# STM32MP157 register map
File version: 1.7
CPU: CM4 r0p1, little endian, no MPU, FPU, 4 interrupt priority bits
Registers are 32-bit, read-write, reset 0x0 unless marked. A register's access mark holds for its fields unless they carry their own. Offsets are from the block's base; [hi:lo] are bit positions; {n}, {i} and the like mark numbered series; 'fields as' and 'values as' point back to an identical list.

## RCC (part 2 of 2)
Base 0x50000000
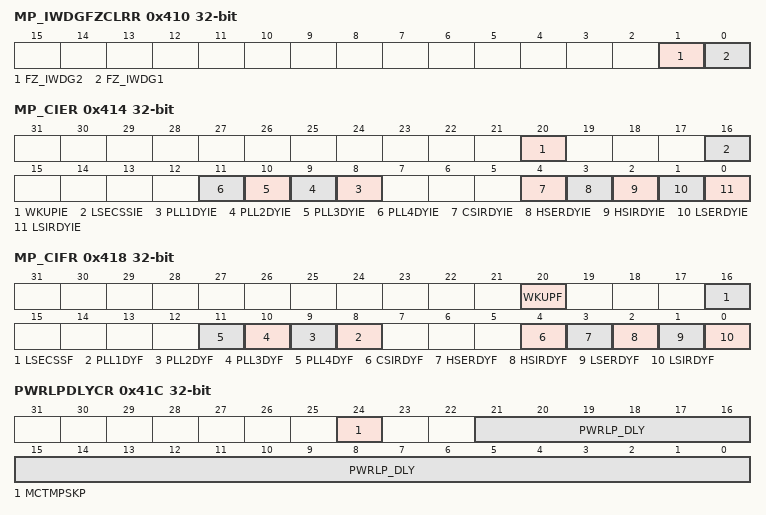
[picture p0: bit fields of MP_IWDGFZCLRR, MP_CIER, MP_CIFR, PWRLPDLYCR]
0x410 MP_IWDGFZCLRR — This register is used by the BOOTROM in order to unfreeze the IWDGs clocks. Writing has no effect, reading will return the effective values of the corresponding bits. Writing a clears the corresponding bit to . If TZEN = , this register can only be modified in secure mode.
  [1] FZ_IWDG2, [0] FZ_IWDG1
0x414 MP_CIER — This register shall be used by the MPU to control the interrupt source enable. Refer to Section10.5: RCC interrupts for more details. If TZEN = , this register can only be modified in secure mode.
  [20] WKUPIE, [16] LSECSSIE, [n+7] PLL{n}DYIE (n=1..4), [4] CSIRDYIE, [3] HSERDYIE, [2] HSIRDYIE, [1] LSERDYIE, [0] LSIRDYIE
0x418 MP_CIFR — This register shall be used by the MPU in order to read and clear the interrupt flags.Writing has no effect, writing will clear the corresponding flag.Refer to Section10.5: RCC interrupts for more details. If TZEN = , this register can only be modified in secure mode.
  [20] WKUPF, [16] LSECSSF, [n+7] PLL{n}DYF (n=1..4), [4] CSIRDYF, [3] HSERDYF, [2] HSIRDYF, [1] LSERDYF, [0] LSIRDYF
0x41C PWRLPDLYCR — This register is used to program the delay between the moment where the system exits from one of the Stop modes, and the moment where it is allowed to enable the PLLs and provide a clock to bridges and processors. If TZEN = , this register can only be modified in secure mode.
  [24] MCTMPSKP, [21:0] PWRLP_DLY
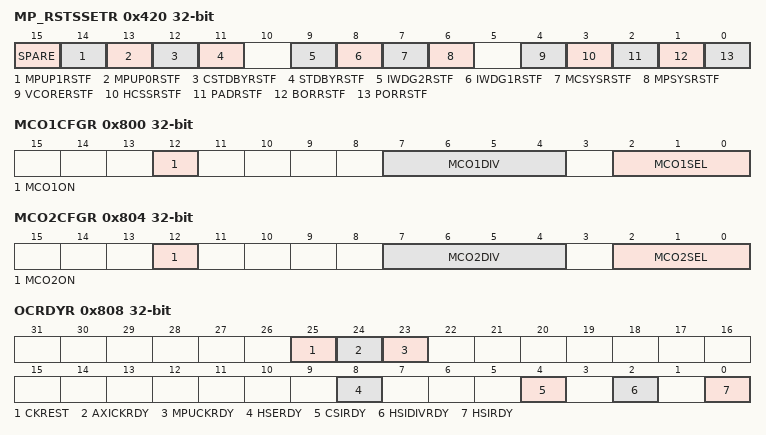
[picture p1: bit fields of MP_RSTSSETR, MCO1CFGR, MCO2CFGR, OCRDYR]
0x420 MP_RSTSSETR — This register is dedicated to the BOOTROM code in order to update the reset source. This register is updated by the BOOTROM code, after a power-on reset (por_rst), a system reset (nreset), or an exit from Standby or CStandby. The application software shall not use this register. In order to identify the reset source, the MPU application must use RCC MPU Reset Status Clear Register (RCC_MP_RSTSCLRR), and the MCU application must use the RCC MCU Reset Status Clear Register (RCC_MC_RSTSCLRR).Writing has no effect, reading will return the effective values of the corresponding bits. Writing a sets the corresponding bit to .Refer to Section10.3.13: Reset source identification for details.The register is located in VDDCORE.If TZEN = , this register can only be modified in secure mode.
  [15] SPARE, [14] MPUP1RSTF, [13] MPUP0RSTF, [12] CSTDBYRSTF, [11] STDBYRSTF, [9] IWDG2RSTF, [8] IWDG1RSTF, [7] MCSYSRSTF, [6] MPSYSRSTF, [4] VCORERSTF, [3] HCSSRSTF, [2] PADRSTF, [1] BORRSTF, [0] PORRSTF
0x800 MCO1CFGR — This register is used to select the clock generated on MCO1 output.
  [12] MCO1ON, [7:4] MCO1DIV, [2:0] MCO1SEL
0x804 MCO2CFGR — This register is used to select the clock generated on MCO2 output.
  [12] MCO2ON, [7:4] MCO2DIV, [2:0] MCO2SEL
0x808 OCRDYR ro — This is a read-only access register, It contains the status flags of oscillators. Writing has no effect.
  [25] CKREST, [24] AXICKRDY, [23] MPUCKRDY, [8] HSERDY, [4] CSIRDY, [2] HSIDIVRDY, [0] HSIRDY
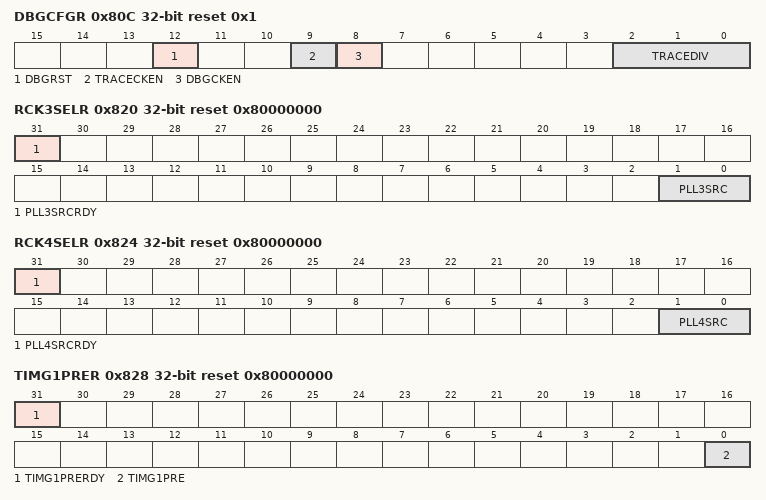
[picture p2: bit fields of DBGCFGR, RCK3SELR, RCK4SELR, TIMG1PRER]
0x80C DBGCFGR reset 0x1 — This is register contains the enable control of the debug and trace function, and the clock divider for the trace function.
  [12] DBGRST, [9] TRACECKEN, [8] DBGCKEN, [2:0] TRACEDIV
0x820 RCK3SELR access per field reset 0x80000000 — This register is used to select the reference clock for PLL3. If TZEN = MCKPROT = , this register can only be modified in secure mode.
  [31] PLL3SRCRDY ro, [1:0] PLL3SRC rw
0x824 RCK4SELR access per field reset 0x80000000 — This register is used to select the reference clock for PLL4.
  [31] PLL4SRCRDY ro, [1:0] PLL4SRC rw
0x828 TIMG1PRER access per field reset 0x80000000 — This register is used to control the prescaler value of timers located into APB1 domain. It concerns TIM2, TIM3, TIM4, TIM5, TIM6, TIM7, TIM12, TIM13 and TIM14. Refer to Section: Sub-system clock generation for additional information.
  [31] TIMG1PRERDY ro, [0] TIMG1PRE rw
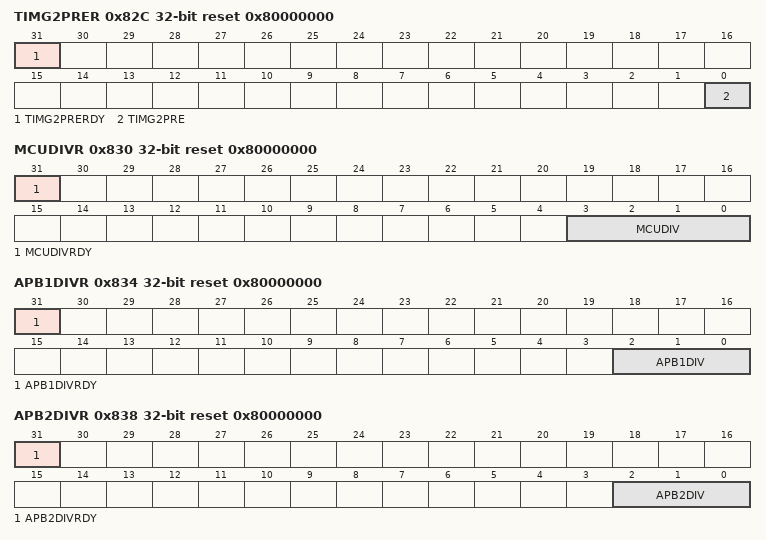
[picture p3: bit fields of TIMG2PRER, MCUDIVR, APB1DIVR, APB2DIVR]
0x82C TIMG2PRER access per field reset 0x80000000 — This register is used to control the prescaler value of timers located into APB2 domain. It concerns TIM1, TIM8, TIM15, TIM16, and TIM17. Refer to Section: Sub-system clock generation for additional information.
  [31] TIMG2PRERDY ro, [0] TIMG2PRE rw
0x830 MCUDIVR access per field reset 0x80000000 — This register is used to control the MCU sub-system clock prescaler. Refer to Section: Sub-system clock generation for additional information. If TZEN = , this register can only be modified in secure mode.
  [31] MCUDIVRDY ro, [3:0] MCUDIV rw
0x834 APB1DIVR access per field reset 0x80000000 — This register is used to control the APB1 clock prescaler. Refer to section Section1.4.6.3: Sub-System Clock Generation for additional information.
  [31] APB1DIVRDY ro, [2:0] APB1DIV rw
0x838 APB2DIVR access per field reset 0x80000000 — This register is used to control the APB2 clock prescaler. Refer to Section: Sub-system clock generation for additional information.
  [31] APB2DIVRDY ro, [2:0] APB2DIV rw
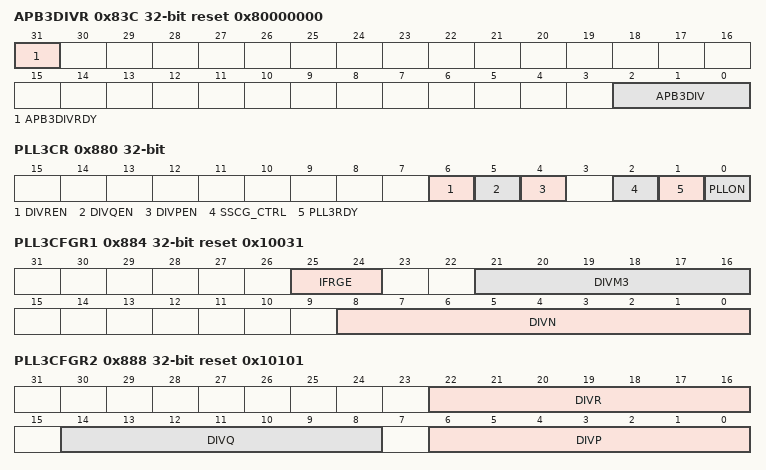
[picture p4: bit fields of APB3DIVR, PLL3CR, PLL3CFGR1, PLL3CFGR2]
0x83C APB3DIVR access per field reset 0x80000000 — This register is used to control the APB3 clock prescaler. Refer to Section: Sub-system clock generation for additional information.
  [31] APB3DIVRDY ro, [2:0] APB3DIV rw
0x880 PLL3CR access per field — This register is used to control the PLL3. If TZEN = MCKPROT = , this register can only be modified in secure mode.
  [6] DIVREN rw, [5] DIVQEN rw, [4] DIVPEN rw, [2] SSCG_CTRL rw, [1] PLL3RDY ro, [0] PLLON rw
0x884 PLL3CFGR1 reset 0x10031 — This register is used to configure the PLL3. If TZEN = MCKPROT = , this register can only be modified in secure mode.
  [25:24] IFRGE, [21:16] DIVM3, [8:0] DIVN
0x888 PLL3CFGR2 reset 0x10101 — This register is used to configure the PLL3. If TZEN = MCKPROT = , this register can only be modified in secure mode.
  [22:16] DIVR, [14:8] DIVQ, [6:0] DIVP
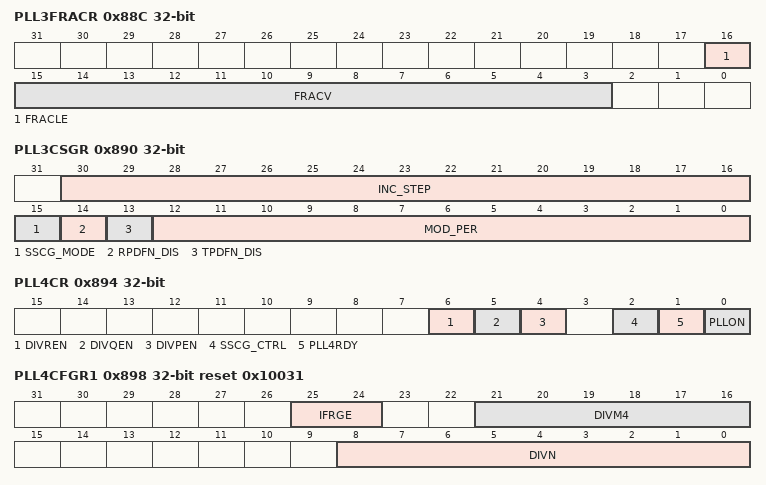
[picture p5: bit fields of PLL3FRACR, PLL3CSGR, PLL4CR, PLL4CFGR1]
0x88C PLL3FRACR — This register is used to fine-tune the frequency of the PLL3 VCO. If TZEN = MCKPROT = , this register can only be modified in secure mode.
  [16] FRACLE, [15:3] FRACV
0x890 PLL3CSGR — This register is used to configure the PLL3.It is not recommended to change the content of this register when the PLL3 is enabled (PLLON = ). Refer to Section: Using the PLLs in spread spectrum mode for details. If TZEN = MCKPROT = , this register can only be modified in secure mode.
  [30:16] INC_STEP, [15] SSCG_MODE, [14] RPDFN_DIS, [13] TPDFN_DIS, [12:0] MOD_PER
0x894 PLL4CR access per field — This register is used to control the PLL4.
  [6] DIVREN rw, [5] DIVQEN rw, [4] DIVPEN rw, [2] SSCG_CTRL rw, [1] PLL4RDY ro, [0] PLLON rw
0x898 PLL4CFGR1 reset 0x10031 — This register is used to configure the PLL4.
  [25:24] IFRGE, [21:16] DIVM4, [8:0] DIVN
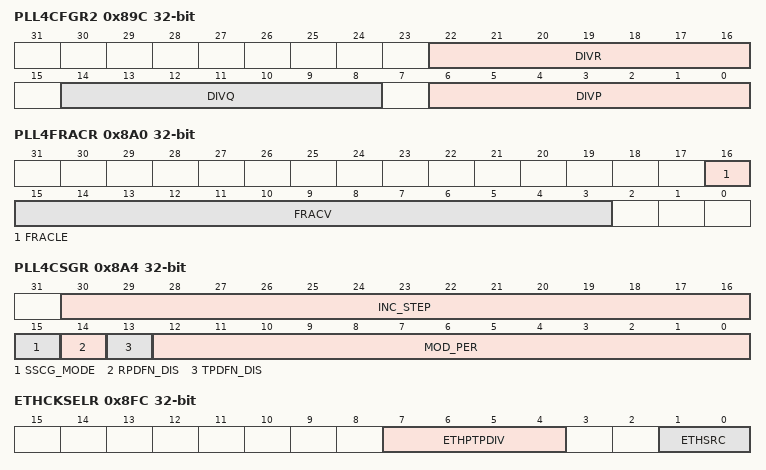
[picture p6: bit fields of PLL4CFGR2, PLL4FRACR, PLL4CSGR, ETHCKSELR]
0x89C PLL4CFGR2 — This register is used to configure the PLL4.
  [22:16] DIVR, [14:8] DIVQ, [6:0] DIVP
0x8A0 PLL4FRACR — This register is used to fine-tune the frequency of the PLL4 VCO.
  [16] FRACLE, [15:3] FRACV
0x8A4 PLL4CSGR — This register is used to configure the PLL4.It is not recommended to change the content of this register when the PLL4 is enabled (PLLON = ). Refer to Section: Using the PLLs in spread spectrum mode for details. If TZEN = MCKPROT = , this register can only be modified in secure mode.
  fields as PLL3CSGR
0x8C0 I2C12CKSELR — This register is used to control the selection of the kernel clock for the I2C1 and I2C2. Note that changing the clock source on-the-fly is allowed, and will not generate any timing violation, however the user has to ensure that both the previous and the new clock sources are present during the switching, and for the whole transition time. Refer to Section: Clock enabling delays.
  [2:0] I2C12SRC
0x8C4 I2C35CKSELR — This register is used to control the selection of the kernel clock for the I2C3 and I2C5. Note that changing the clock source on-the-fly is allowed, and will not generate any timing violation, however the user has to ensure that both the previous and the new clock sources are present during the switching, and for the whole transition time. Refer to Section: Clock enabling delays.
  [2:0] I2C35SRC
0x8C8 SAI1CKSELR — This register is used to control the selection of the kernel clock for the SAI1 and DFSDM audio clock. Note that changing the clock source on-the-fly is allowed, and will not generate any timing violation, however the user has to ensure that both the previous and the new clock sources are present during the switching, and for the whole transition time. Refer to Section: Clock enabling delays.
  [2:0] SAI1SRC
{0x8C4+4i} SAI{i}CKSELR (i=2..4) — This register is used to control the selection of the kernel clock for the SAI{i}. Note that changing the clock source on-the-fly is allowed, and will not generate any timing violation, however the user has to ensure that both the previous and the new clock sources are present during the switching, and for the whole transition time. Refer to Section: Clock enabling delays.
  [2:0] SAI{i}SRC
0x8D8 SPI2S1CKSELR — This register is used to control the selection of the kernel clock for the SPI/I2S1. Note that changing the clock source on-the-fly is allowed, and will not generate any timing violation, however the user has to ensure that both the previous and the new clock sources are present during the switching, and for the whole transition time. Refer to Section: Clock enabling delays.
  [2:0] SPI1SRC
0x8DC SPI2S23CKSELR — This register is used to control the selection of the kernel clock for the SPI/I2S2,3. Note that changing the clock source on-the-fly is allowed, and will not generate any timing violation, however the user has to ensure that both the previous and the new clock sources are present during the switching, and for the whole transition time. Refer to Section: Clock enabling delays.
  [2:0] SPI23SRC
0x8E0 SPI45CKSELR — This register is used to control the selection of the kernel clock for the SPI4,5. Note that changing the clock source on-the-fly is allowed, and will not generate any timing violation, however the user has to ensure that both the previous and the new clock sources are present during the switching, and for the whole transition time. Refer to Section: Clock enabling delays.
  [2:0] SPI45SRC
0x8E4 UART6CKSELR — This register is used to control the selection of the kernel clock for the USART6. Note that changing the clock source on-the-fly is allowed, and will not generate any timing violation, however the user has to ensure that both the previous and the new clock sources are present during the switching, and for the whole transition time. Refer to Section: Clock enabling delays.
  [2:0] UART6SRC
0x8E8 UART24CKSELR — This register is used to control the selection of the kernel clock for the USART2 and UART4. Note that changing the clock source on-the-fly is allowed, and will not generate any timing violation, however the user has to ensure that both the previous and the new clock sources are present during the switching, and for the whole transition time. Refer to Section: Clock enabling delays.
  [2:0] UART24SRC
0x8EC UART35CKSELR — This register is used to control the selection of the kernel clock for the USART3 and UART5. Note that changing the clock source on-the-fly is allowed, and will not generate any timing violation, however the user has to ensure that both the previous and the new clock sources are present during the switching, and for the whole transition time. Refer to Section: Clock enabling delays.
  [2:0] UART35SRC
0x8F0 UART78CKSELR — This register is used to control the selection of the kernel clock for the UART7 and UART8. Note that changing the clock source on-the-fly is allowed, and will not generate any timing violation, however the user has to ensure that both the previous and the new clock sources are present during the switching, and for the whole transition time. Refer to Section: Clock enabling delays.
  [2:0] UART78SRC
0x8F4 SDMMC12CKSELR reset 0x3 — This register is used to control the selection of the kernel clock for the SDMMC1 and SDMMC2. Note that changing the clock source on-the-fly is allowed, and will not generate any timing violation, however the user has to ensure that both the previous and the new clock sources are present during the switching, and for the whole transition time. Refer to Section: Clock enabling delays.
  [2:0] SDMMC12SRC
0x8F8 SDMMC3CKSELR — This register is used to control the selection of the kernel clock for the SDMMC3. Note that changing the clock source on-the-fly is allowed, and will not generate any timing violation, however the user has to ensure that both the previous and the new clock sources are present during the switching, and for the whole transition time. Refer to Section: Clock enabling delays.
  [2:0] SDMMC3SRC
0x8FC ETHCKSELR — This register is used to control the selection of the kernel clock for the ETH block. Note that changing the clock source on-the-fly is allowed, and will not generate any timing violation, however the user has to ensure that both the previous and the new clock sources are present during the switching, and for the whole transition time. Refer to Section: Clock enabling delays.
  [7:4] ETHPTPDIV, [1:0] ETHSRC
0x900 QSPICKSELR — This register is used to control the selection of the kernel clock for the QUADSPI. Note that changing the clock source on-the-fly is allowed, and will not generate any timing violation, however the user has to ensure that both the previous and the new clock sources are present during the switching, and for the whole transition time. Refer to Section: Clock enabling delays.
  [1:0] QSPISRC
0x904 FMCCKSELR — This register is used to control the selection of the kernel clock for the FMC block. Note that changing the clock source on-the-fly is allowed, and will not generate any timing violation, however the user has to ensure that both the previous and the new clock sources are present during the switching, and for the whole transition time. Refer to Section: Clock enabling delays.
  [1:0] FMCSRC
0x90C FDCANCKSELR — This register is used to control the selection of the kernel clock for the FDCAN block. Note that changing the clock source on-the-fly is allowed, and will not generate any timing violation, however the user has to ensure that both the previous and the new clock sources are present during the switching, and for the whole transition time. Refer to Section: Clock enabling delays.
  [1:0] FDCANSRC
0x914 SPDIFCKSELR — This register is used to control the selection of the kernel clock for the SPDIFRX. Note that changing the clock source on-the-fly is allowed, and will not generate any timing violation, however the user has to ensure that both the previous and the new clock sources are present during the switching, and for the whole transition time. Refer to Section: Clock enabling delays.
  [1:0] SPDIFSRC
0x918 CECCKSELR — This register is used to control the selection of the kernel clock for the CEC-HDMI.
  [1:0] CECSRC
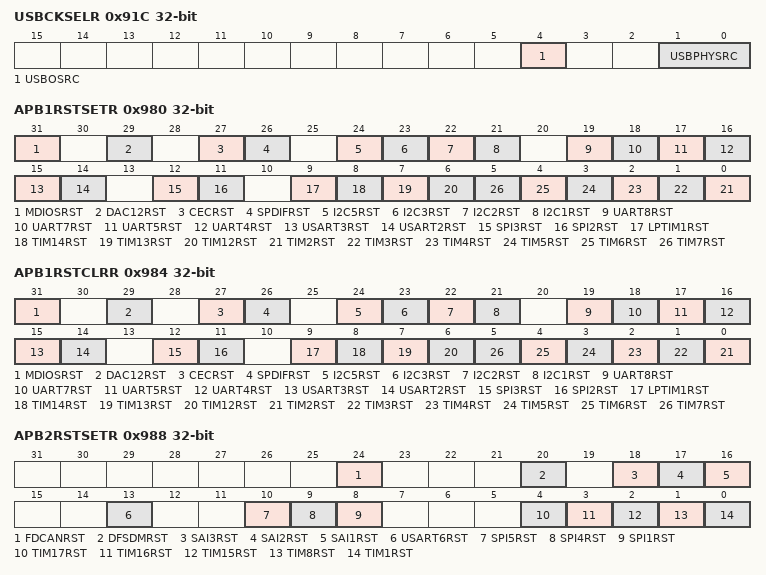
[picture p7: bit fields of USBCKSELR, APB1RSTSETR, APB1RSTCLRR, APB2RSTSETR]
0x91C USBCKSELR — This register is used to control the selection of the kernel clock for the USBPHY PLL of the USB HOST and USB OTG
  [4] USBOSRC, [1:0] USBPHYSRC
0x920 RNG2CKSELR — This register is used to control the selection of the kernel clock for the RNG2.
  [1:0] RNG2SRC
0x924 DSICKSELR — This register is used to control the selection of the kernel clock for the DSI block.
  [0] DSISRC
0x928 ADCCKSELR — This register is used to control the selection of the kernel clock for the ADC block.
  [1:0] ADCSRC
0x92C LPTIM45CKSELR — This register is used to control the selection of the kernel clock for the LPTIM4 and LPTIM5 blocks.
  [2:0] LPTIM45SRC
0x930 LPTIM23CKSELR — This register is used to control the selection of the kernel clock for the LPTIM2 and LPTIM3 blocks.
  [2:0] LPTIM23SRC
0x934 LPTIM1CKSELR — This register is used to control the selection of the kernel clock for the LPTIM1 block.
  [2:0] LPTIM1SRC
0x980 APB1RSTSETR — This register is used to activate the reset of the corresponding peripheral.
  [31] MDIOSRST, [29] DAC12RST, [27] CECRST, [26] SPDIFRST, [24] I2C5RST, [23] I2C3RST, [22] I2C2RST, [21] I2C1RST, [19] UART8RST, [18] UART7RST, [17] UART5RST, [16] UART4RST, [15] USART3RST, [14] USART2RST, [12] SPI3RST, [11] SPI2RST, [9] LPTIM1RST, [8] TIM14RST, [7] TIM13RST, [6] TIM12RST, [n-2] TIM{n}RST (n=2..7)
0x984 APB1RSTCLRR — This register is used to release the reset of the corresponding peripheral.
  fields as APB1RSTSETR
0x988 APB2RSTSETR — This register is used to activate the reset of the corresponding peripheral.
  [24] FDCANRST, [20] DFSDMRST, [18] SAI3RST, [17] SAI2RST, [16] SAI1RST, [13] USART6RST, [10] SPI5RST, [9] SPI4RST, [8] SPI1RST, [4] TIM17RST, [3] TIM16RST, [2] TIM15RST, [1] TIM8RST, [0] TIM1RST
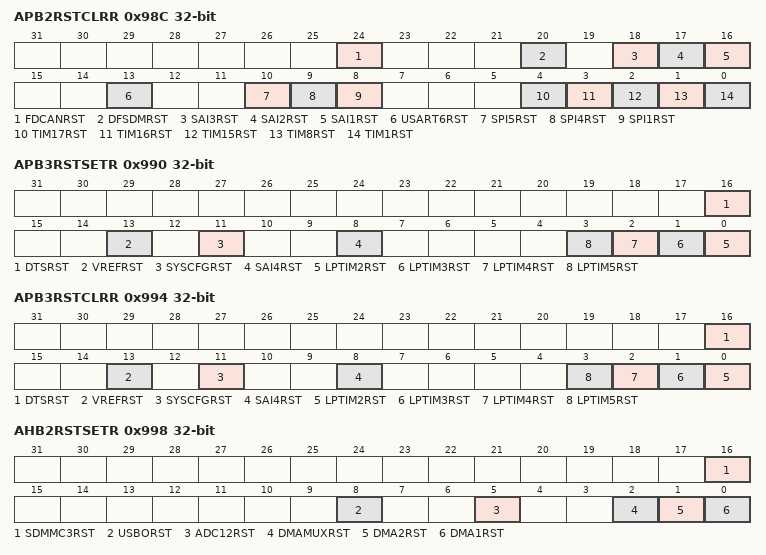
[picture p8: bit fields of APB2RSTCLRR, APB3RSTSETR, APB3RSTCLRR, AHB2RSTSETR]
0x98C APB2RSTCLRR — This register is used to release the reset of the corresponding peripheral.
  fields as APB2RSTSETR
0x990 APB3RSTSETR — This register is used to activate the reset of the corresponding peripheral.
  [16] DTSRST, [13] VREFRST, [11] SYSCFGRST, [8] SAI4RST, [n-2] LPTIM{n}RST (n=2..5)
0x994 APB3RSTCLRR — This register is used to release the reset of the corresponding peripheral.
  fields as APB3RSTSETR
0x998 AHB2RSTSETR — This register is used to activate the reset of the corresponding peripheral.
  [16] SDMMC3RST, [8] USBORST, [5] ADC12RST, [2] DMAMUXRST, [1] DMA2RST, [0] DMA1RST
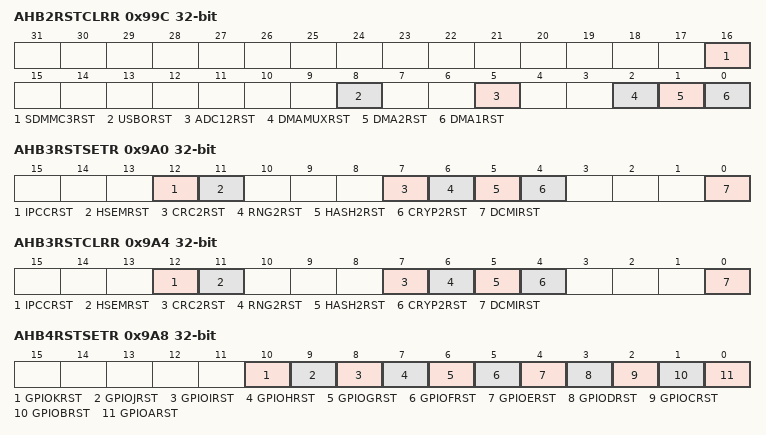
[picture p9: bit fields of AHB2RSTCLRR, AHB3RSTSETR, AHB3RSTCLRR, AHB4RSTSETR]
0x99C AHB2RSTCLRR — This register is used to release the reset of the corresponding peripheral.
  fields as AHB2RSTSETR
0x9A0 AHB3RSTSETR — This register is used to activate the reset of the corresponding peripheral.
  [12] IPCCRST, [11] HSEMRST, [7] CRC2RST, [6] RNG2RST, [5] HASH2RST, [4] CRYP2RST, [0] DCMIRST
0x9A4 AHB3RSTCLRR — This register is used to release the reset of the corresponding peripheral.
  fields as AHB3RSTSETR
0x9A8 AHB4RSTSETR — This register is used to activate the reset of the corresponding peripheral
  [10] GPIOKRST, [9] GPIOJRST, [8] GPIOIRST, [7] GPIOHRST, [6] GPIOGRST, [5] GPIOFRST, [4] GPIOERST, [3] GPIODRST, [2] GPIOCRST, [1] GPIOBRST, [0] GPIOARST
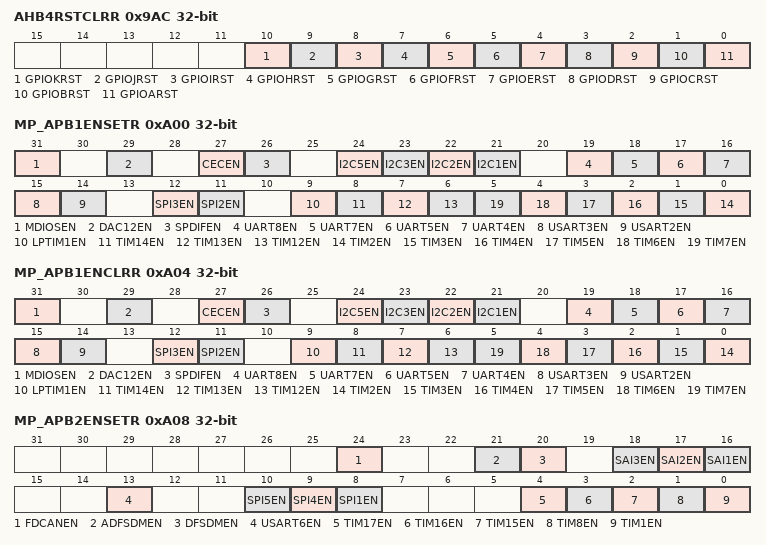
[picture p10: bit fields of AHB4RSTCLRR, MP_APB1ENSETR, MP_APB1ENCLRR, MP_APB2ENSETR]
0x9AC AHB4RSTCLRR — This register is used to release the reset of the corresponding peripheral.
  fields as AHB4RSTSETR
0xA00 MP_APB1ENSETR — This register is used to set the peripheral clock enable bit
  [31] MDIOSEN, [29] DAC12EN, [27] CECEN, [26] SPDIFEN, [24] I2C5EN, [23] I2C3EN, [22] I2C2EN, [21] I2C1EN, [19] UART8EN, [18] UART7EN, [17] UART5EN, [16] UART4EN, [15] USART3EN, [14] USART2EN, [12] SPI3EN, [11] SPI2EN, [9] LPTIM1EN, [8] TIM14EN, [7] TIM13EN, [6] TIM12EN, [n-2] TIM{n}EN (n=2..7)
0xA04 MP_APB1ENCLRR — This register is used to clear the peripheral clock enable bit
  fields as MP_APB1ENSETR
0xA08 MP_APB2ENSETR — This register is used to set the peripheral clock enable bit
  [24] FDCANEN, [21] ADFSDMEN, [20] DFSDMEN, [18] SAI3EN, [17] SAI2EN, [16] SAI1EN, [13] USART6EN, [10] SPI5EN, [9] SPI4EN, [8] SPI1EN, [4] TIM17EN, [3] TIM16EN, [2] TIM15EN, [1] TIM8EN, [0] TIM1EN
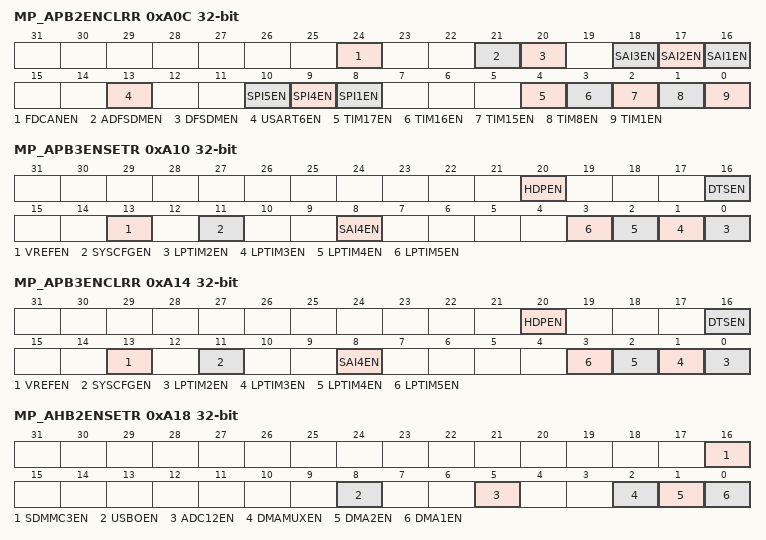
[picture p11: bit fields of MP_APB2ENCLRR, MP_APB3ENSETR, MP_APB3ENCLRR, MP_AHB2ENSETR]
0xA0C MP_APB2ENCLRR — This register is used to clear the peripheral clock enable bit of the corresponding peripheral.
  fields as MP_APB2ENSETR
0xA10 MP_APB3ENSETR — This register is used to set the peripheral clock enable bit
  [20] HDPEN, [16] DTSEN, [13] VREFEN, [11] SYSCFGEN, [8] SAI4EN, [n-2] LPTIM{n}EN (n=2..5)
0xA14 MP_APB3ENCLRR — This register is used to clear the peripheral clock enable bit of the corresponding peripheral.
  fields as MP_APB3ENSETR
0xA18 MP_AHB2ENSETR — This register is used to set the peripheral clock enable bit of the corresponding peripheral
  [16] SDMMC3EN, [8] USBOEN, [5] ADC12EN, [2] DMAMUXEN, [1] DMA2EN, [0] DMA1EN
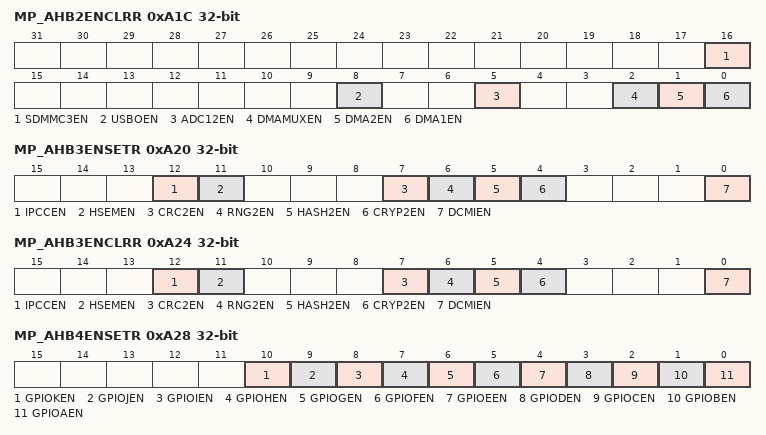
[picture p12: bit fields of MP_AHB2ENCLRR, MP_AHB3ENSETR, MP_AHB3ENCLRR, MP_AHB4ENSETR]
0xA1C MP_AHB2ENCLRR — This register is used to clear the peripheral clock enable bit of the corresponding peripheral.
  fields as MP_AHB2ENSETR
0xA20 MP_AHB3ENSETR — This register is used to set the peripheral clock enable bit of the corresponding peripheral
  [12] IPCCEN, [11] HSEMEN, [7] CRC2EN, [6] RNG2EN, [5] HASH2EN, [4] CRYP2EN, [0] DCMIEN
0xA24 MP_AHB3ENCLRR — This register is used to clear the peripheral clock enable bit of the corresponding peripheral.
  fields as MP_AHB3ENSETR
0xA28 MP_AHB4ENSETR — This register is used to set the peripheral clock enable bit of the corresponding peripheral to . It shall be used to allocate a peripheral to the MPU.
  [10] GPIOKEN, [9] GPIOJEN, [8] GPIOIEN, [7] GPIOHEN, [6] GPIOGEN, [5] GPIOFEN, [4] GPIOEEN, [3] GPIODEN, [2] GPIOCEN, [1] GPIOBEN, [0] GPIOAEN
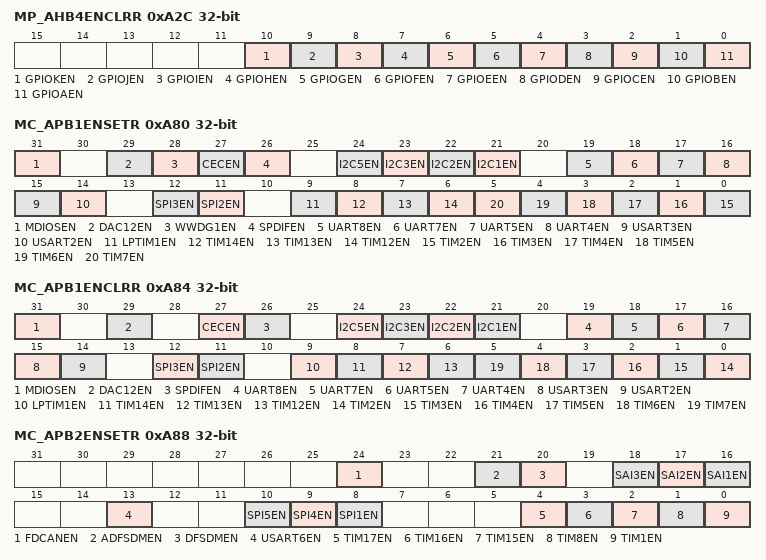
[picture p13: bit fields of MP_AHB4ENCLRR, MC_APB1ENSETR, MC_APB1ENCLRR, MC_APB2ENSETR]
0xA2C MP_AHB4ENCLRR — This register is used to clear the peripheral clock enable bit
  fields as MP_AHB4ENSETR
0xA38 MP_MLAHBENSETR reset 0x10 — This register is used to set the peripheral clock enable bit
  [4] RETRAMEN
0xA3C MP_MLAHBENCLRR reset 0x10 — This register is used to clear the peripheral clock enable bit.
  [4] RETRAMEN
0xA80 MC_APB1ENSETR — This register is used to set the peripheral clock enable bit of the corresponding peripheral to . It shall be used to allocate a peripheral to the MCU. Writing has no effect, reading will return . Writing a sets the corresponding bit to .
  [31] MDIOSEN, [29] DAC12EN, [28] WWDG1EN, [27] CECEN, [26] SPDIFEN, [24] I2C5EN, [23] I2C3EN, [22] I2C2EN, [21] I2C1EN, [19] UART8EN, [18] UART7EN, [17] UART5EN, [16] UART4EN, [15] USART3EN, [14] USART2EN, [12] SPI3EN, [11] SPI2EN, [9] LPTIM1EN, [8] TIM14EN, [7] TIM13EN, [6] TIM12EN, [n-2] TIM{n}EN (n=2..7)
0xA84 MC_APB1ENCLRR — This register is used to clear the peripheral clock enable bit of the corresponding peripheral.
  fields as MP_APB1ENSETR
0xA88 MC_APB2ENSETR — This register is used to set the peripheral clock enable bit
  fields as MP_APB2ENSETR
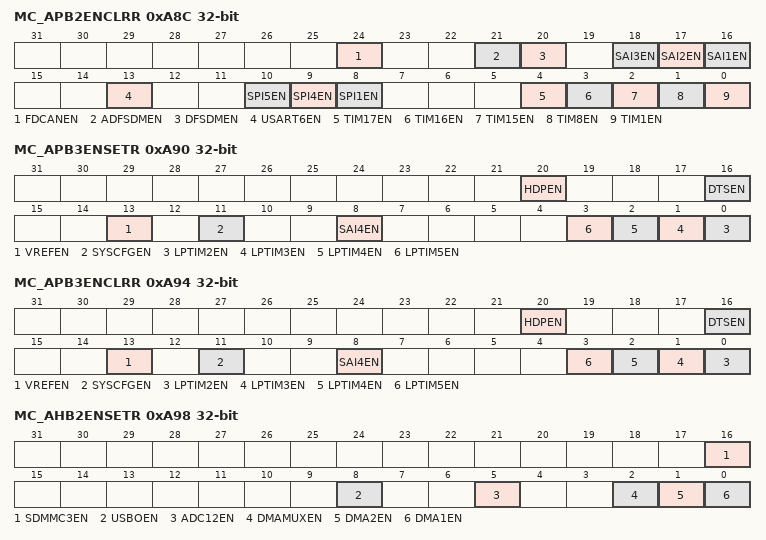
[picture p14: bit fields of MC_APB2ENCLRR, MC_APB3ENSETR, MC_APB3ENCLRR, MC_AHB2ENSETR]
0xA8C MC_APB2ENCLRR — This register is used to clear the peripheral clock enable bit
  fields as MP_APB2ENSETR
0xA90 MC_APB3ENSETR — This register is used to set the peripheral clock enable bit
  fields as MP_APB3ENSETR
0xA94 MC_APB3ENCLRR — This register is used to clear the peripheral clock enable bit
  fields as MP_APB3ENSETR
0xA98 MC_AHB2ENSETR — This register is used to set the peripheral clock enable bit
  fields as MP_AHB2ENSETR
0xA9C MC_AHB2ENCLRR — This register is used to clear the peripheral clock enable bit
  fields as MP_AHB2ENSETR
0xAA0 MC_AHB3ENSETR — This register is used to set the peripheral clock enable bit
  fields as MP_AHB3ENSETR
0xAA4 MC_AHB3ENCLRR — This register is used to clear the peripheral clock enable bit
  fields as MP_AHB3ENSETR
0xAA8 MC_AHB4ENSETR — This register is used to set the peripheral clock enable bit
  fields as MP_AHB4ENSETR
0xAAC MC_AHB4ENCLRR — This register is used to clear the peripheral clock enable bit
  fields as MP_AHB4ENSETR
0xAB0 MC_AXIMENSETR — This register is used to set the peripheral clock enable bit
  [0] SYSRAMEN
0xAB4 MC_AXIMENCLRR — This register is used to clear the peripheral clock enable bit
  [0] SYSRAMEN
0xAB8 MC_MLAHBENSETR reset 0x10 — This register is used to set the peripheral clock enable bit
  [4] RETRAMEN
0xABC MC_MLAHBENCLRR reset 0x10 — This register is used to clear the peripheral clock enable bit
  [4] RETRAMEN
0xB00 MP_APB1LPENSETR reset 0xADEFDBFF — This register is used by the MCU in order to clear the PERxLPEN bits
  [31] MDIOSLPEN, [29] DAC12LPEN, [27] CECLPEN, [26] SPDIFLPEN, [24] I2C5LPEN, [23] I2C3LPEN, [22] I2C2LPEN, [21] I2C1LPEN, [19] UART8LPEN, [18] UART7LPEN, [17] UART5LPEN, [16] UART4LPEN, [15] USART3LPEN, [14] USART2LPEN, [12] SPI3LPEN, [11] SPI2LPEN, [9] LPTIM1LPEN, [8] TIM14LPEN, [7] TIM13LPEN, [6] TIM12LPEN, [n-2] TIM{n}LPEN (n=2..7)
0xB04 MP_APB1LPENCLRR reset 0xADEFDBFF — This register is used by the MPU in order to clear the PERxLPEN bits .
  fields as MP_APB1LPENSETR
0xB08 MP_APB2LPENSETR reset 0x137271F — This register is used by the MCU in order to clear the PERxLPEN bits
  [24] FDCANLPEN, [21] ADFSDMLPEN, [20] DFSDMLPEN, [18] SAI3LPEN, [17] SAI2LPEN, [16] SAI1LPEN, [13] USART6LPEN, [10] SPI5LPEN, [9] SPI4LPEN, [8] SPI1LPEN, [4] TIM17LPEN, [3] TIM16LPEN, [2] TIM15LPEN, [1] TIM8LPEN, [0] TIM1LPEN
0xB0C MP_APB2LPENCLRR reset 0x137271F — This register is used by the MCU in order to clear the PERxLPEN bits
  fields as MP_APB2LPENSETR
0xB10 MP_APB3LPENSETR reset 0x3290F — This register is used by the MCU in order to clear the PERxLPEN bits
  [16] DTSLPEN, [13] VREFLPEN, [11] SYSCFGLPEN, [8] SAI4LPEN, [n-2] LPTIM{n}LPEN (n=2..5)
0xB14 MP_APB3LPENCLRR reset 0x3290F — This register is used by the MCU in order to clear the PERxLPEN bits
  fields as MP_APB3LPENSETR
0xB18 MP_AHB2LPENSETR reset 0x10127 — This register is used by the MPU in order to set the PERxLPEN bit.
  [16] SDMMC3LPEN, [8] USBOLPEN, [5] ADC12LPEN, [2] DMAMUXLPEN, [1] DMA2LPEN, [0] DMA1LPEN
0xB1C MP_AHB2LPENCLRR reset 0x10127 — This register is used by the MCU in order to clear the PERxLPEN bits
  fields as MP_AHB2LPENSETR
0xB20 MP_AHB3LPENSETR reset 0x18F1 — This register is used by the MPU
  [12] IPCCLPEN, [11] HSEMLPEN, [7] CRC2LPEN, [6] RNG2LPEN, [5] HASH2LPEN, [4] CRYP2LPEN, [0] DCMILPEN
0xB24 MP_AHB3LPENCLRR reset 0x18F1 — This register is used by the MPU in order to clear the PERxLPEN bit
  fields as MP_AHB3LPENSETR
0xB28 MP_AHB4LPENSETR reset 0x7FF — This register is used by the MPU
  [10] GPIOKLPEN, [9] GPIOJLPEN, [8] GPIOILPEN, [7] GPIOHLPEN, [6] GPIOGLPEN, [5] GPIOFLPEN, [4] GPIOELPEN, [3] GPIODLPEN, [2] GPIOCLPEN, [1] GPIOBLPEN, [0] GPIOALPEN
0xB2C MP_AHB4LPENCLRR reset 0x7FF — This register is used by the MPU
  fields as MP_AHB4LPENSETR
0xB30 MP_AXIMLPENSETR reset 0x1 — This register is used by the MPU
  [0] SYSRAMLPEN
0xB34 MP_AXIMLPENCLRR reset 0x1 — This register is used by the MPU
  [0] SYSRAMLPEN
0xB38 MP_MLAHBLPENSETR reset 0x17 — This register is used by the MPU in order to set the PERxLPEN bit
  [4] RETRAMLPEN, [2] SRAM34LPEN, [1] SRAM2LPEN, [0] SRAM1LPEN
0xB3C MP_MLAHBLPENCLRR reset 0x17 — This register is used by the MPU in order to clear the PERxLPEN bit
  [4] RETRAMLPEN, [2] SRAM34LPEN, [1] SRAM2LPEN, [0] SRAM1LPEN
0xB80 MC_APB1LPENSETR reset 0xBDEFDBFF — This register is used by the MCU in order to set the PERxLPEN bit.
  [31] MDIOSLPEN, [29] DAC12LPEN, [28] WWDG1LPEN, [27] CECLPEN, [26] SPDIFLPEN, [24] I2C5LPEN, [23] I2C3LPEN, [22] I2C2LPEN, [21] I2C1LPEN, [19] UART8LPEN, [18] UART7LPEN, [17] UART5LPEN, [16] UART4LPEN, [15] USART3LPEN, [14] USART2LPEN, [12] SPI3LPEN, [11] SPI2LPEN, [9] LPTIM1LPEN, [8] TIM14LPEN, [7] TIM13LPEN, [6] TIM12LPEN, [n-2] TIM{n}LPEN (n=2..7)
0xB84 MC_APB1LPENCLRR reset 0xBDEFDBFF — This register is used by the MCU in order to clear the PERxLPEN bits
  fields as MC_APB1LPENSETR
0xB88 MC_APB2LPENSETR reset 0x137271F — This register is used by the MCU in order to set the PERxLPEN bit.
  fields as MP_APB2LPENSETR
0xB8C MC_APB2LPENCLRR reset 0x137271F — This register is used by the MCU in order to clear the PERxLPEN bit
  fields as MP_APB2LPENSETR
0xB90 MC_APB3LPENSETR reset 0x3290F — This register is used by the MCU in order to set the PERxLPEN bit.
  fields as MP_APB3LPENSETR
0xB94 MC_APB3LPENCLRR reset 0x3290F — This register is used by the MCU in order to clear the PERxLPEN bit
  fields as MP_APB3LPENSETR
0xB98 MC_AHB2LPENSETR reset 0x10127 — This register is used by the MCU in order to set the PERxLPEN bit.
  fields as MP_AHB2LPENSETR
0xB9C MC_AHB2LPENCLRR reset 0x10127 — This register is used by the MCU in order to clear the PERxLPEN bit
  fields as MP_AHB2LPENSETR
0xBA0 MC_AHB3LPENSETR reset 0x18F1 — This register is used by the MCU in order to set the PERxLPEN bit.
  fields as MP_AHB3LPENSETR
0xBA4 MC_AHB3LPENCLRR reset 0x18F1 — This register is used by the MCU in order to clear the PERxLPEN bit
  fields as MP_AHB3LPENSETR
0xBA8 MC_AHB4LPENSETR reset 0x7FF — This register is used by the MCU in order to set the PERxLPEN bit.
  fields as MP_AHB4LPENSETR
0xBAC MC_AHB4LPENCLRR reset 0x7FF — This register is used by the MCU in order to clear the PERxLPEN bit of the corresponding peripheral.
  fields as MP_AHB4LPENSETR
0xBB0 MC_AXIMLPENSETR reset 0x1 — This register is used by the MCU in order to set the PERxLPEN bit of the corresponding peripheral.
  [0] SYSRAMLPEN
0xBB4 MC_AXIMLPENCLRR reset 0x1 — This register is used by the MCU in order to clear the PERxLPEN bit of the corresponding peripheral.
  [0] SYSRAMLPEN
0xBB8 MC_MLAHBLPENSETR reset 0x17 — This register is used by the MCU in order to set the PERxLPEN bit of the corresponding peripheral.
  [4] RETRAMLPEN, [2] SRAM34LPEN, [1] SRAM2LPEN, [0] SRAM1LPEN
0xBBC MC_MLAHBLPENCLRR reset 0x17 — This register is used by the MCU in order to clear the PERxLPEN bit of the corresponding peripheral.
  [4] RETRAMLPEN, [2] SRAM34LPEN, [1] SRAM2LPEN, [0] SRAM1LPEN
0xC00 MC_RSTSCLRR reset 0x15 — This register is used by the MCU to check the reset source.
  [10] WWDG1RSTF, [9] IWDG2RSTF, [8] IWDG1RSTF, [7] MCSYSRSTF, [6] MPSYSRSTF, [5] MCURSTF, [4] VCORERSTF, [3] HCSSRSTF, [2] PADRSTF, [1] BORRSTF, [0] PORRSTF
0xC14 MC_CIER — This register shall be used by the MCU to control the interrupt source enable. Refer to Section10.5: RCC interrupts for more details.
  fields as MP_CIER
0xC18 MC_CIFR — This register shall be used by the MCU in order to read and clear the interrupt flags.
  fields as MP_CIFR
0xFF4 VERR ro reset 0x11 — This register gives the IP version
  [7:4] MAJREV, [3:0] MINREV
0xFF8 IDR ro reset 0x1 — This register gives the unique identifier of the RCC
  [31:0] ID
0xFFC SIDR ro reset 0xA3C5DD04 — This register gives the decoding space, which is for the RCC of 4 kB.
  [31:0] SID
